VERSION ""

NS_ :

BS_:

BU_: SimBus RxModel

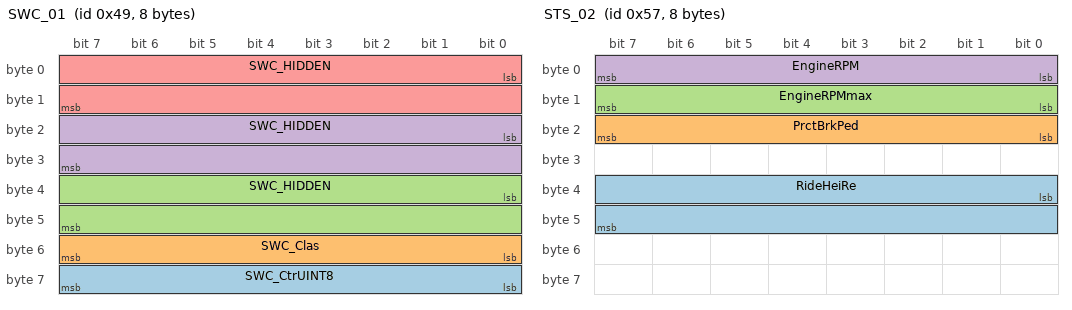
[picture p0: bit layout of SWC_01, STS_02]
BO_ 73 SWC_01: 8 RxModel
 SG_ SWC_CtrUINT8 : 56|8@1+ (1,0) [0|255] "rad" Vector__XXX
 SG_ SWC_Clas : 48|8@1+ (1,0) [0|255] "na" Vector__XXX
 SG_ SWC_HIDDEN : 32|16@1+ (1.06526489E-007,-0.00349066) [-0.00349066|0.003490553456615] "rad" Vector__XXX
 SG_ SWC_HIDDEN : 16|16@1+ (5.999E-006,-0.19659) [-0.19659|0.196554465] "rad" Vector__XXX
 SG_ SWC_HIDDEN : 0|16@1+ (5.999E-006,-0.19659) [-0.19659|0.196554465] "rad" Vector__XXX

BO_ 87 STS_02: 8 SimBus
 SG_ RideHeiRe : 32|16@1+ (0.005,-163.84) [-163.84|163.835] "mps2"  RxModel
 SG_ PrctBrkPed : 16|8@1+ (1,0) [0|255] ""  RxModel
 SG_ EngineRPMmax : 8|8@1+ (50,0) [0|12750] ""  RxModel
 SG_ EngineRPM : 0|8@1+ (50,0) [0|12750] ""  RxModel

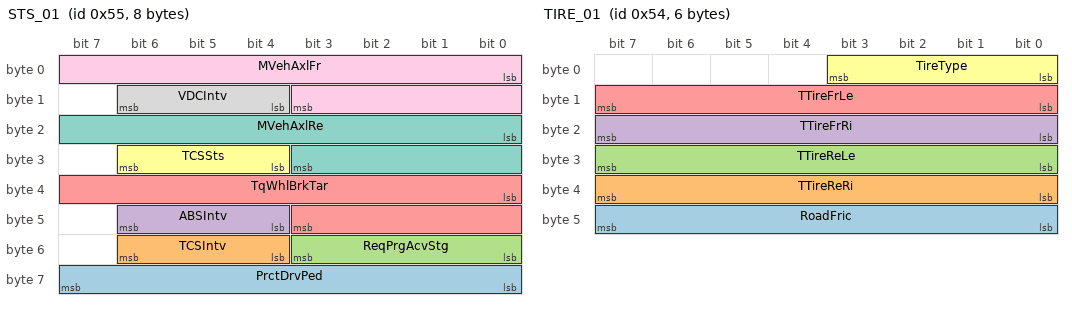
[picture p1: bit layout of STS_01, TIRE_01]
BO_ 85 STS_01: 8 SimBus
 SG_ PrctDrvPed : 56|8@1+ (1,0) [0|255] ""  RxModel
 SG_ TCSIntv : 52|3@1+ (1,0) [0|7] ""  RxModel
 SG_ ReqPrgAcvStg : 48|4@1+ (1,0) [0|15] ""  RxModel
 SG_ ABSIntv : 44|3@1+ (1,0) [0|7] ""  RxModel
 SG_ TqWhlBrkTar : 32|12@1+ (5,0) [0|20475] ""  RxModel
 SG_ TCSSts : 28|3@1+ (1,0) [0|7] ""  RxModel
 SG_ MVehAxlRe : 16|12@1+ (1,0) [0|4095] ""  RxModel
 SG_ VDCIntv : 12|3@1+ (1,0) [0|7] ""  RxModel
 SG_ MVehAxlFr : 0|12@1+ (1,0) [0|4095] ""  RxModel

BO_ 84 TIRE_01: 6 SimBus
 SG_ RoadFric : 40|8@1+ (0.01,0) [0|2.55] ""  RxModel
 SG_ TTireReRi : 32|8@1+ (1,-25) [-25|230] "deg"  RxModel
 SG_ TTireReLe : 24|8@1+ (1,-25) [-25|230] "deg"  RxModel
 SG_ TTireFrRi : 16|8@1+ (1,-25) [-25|230] "deg"  RxModel
 SG_ TTireFrLe : 8|8@1+ (1,-25) [-25|230] "deg"  RxModel
 SG_ TireType : 0|4@1+ (1,0) [0|15] ""  RxModel

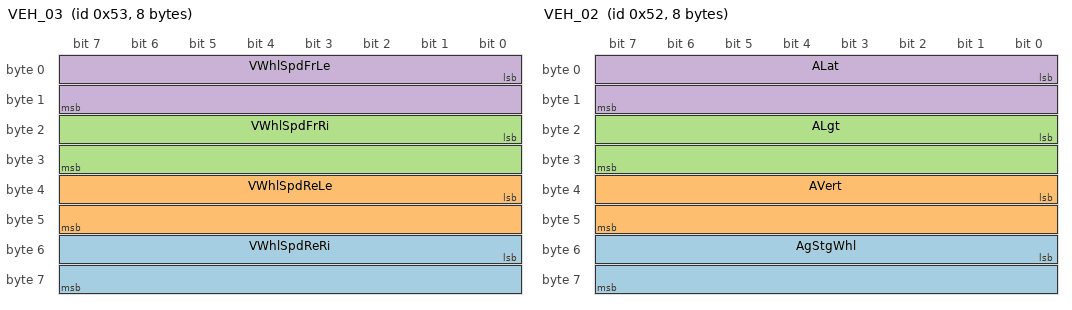
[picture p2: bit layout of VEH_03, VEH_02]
BO_ 83 VEH_03: 8 SimBus
 SG_ VWhlSpdReRi : 48|16@1+ (0.0039,-127.7874) [-127.7874|127.7991] "mps"  RxModel
 SG_ VWhlSpdReLe : 32|16@1+ (0.0039,-127.7874) [-127.7874|127.7991] "mps"  RxModel
 SG_ VWhlSpdFrRi : 16|16@1+ (0.0039,-127.7874) [-127.7874|127.7991] "mps"  RxModel
 SG_ VWhlSpdFrLe : 0|16@1+ (0.0039,-127.7874) [-127.7874|127.7991] "mps"  RxModel

BO_ 82 VEH_02: 8 SimBus
 SG_ AgStgWhl : 48|16@1+ (0.000436252413289189,-14.2942465738336) [-14.2942465738336|14.2955553310734] "rad"  RxModel
 SG_ AVert : 32|16@1+ (0.005,-163.84) [-163.84|163.835] "mps2"  RxModel
 SG_ ALgt : 16|16@1+ (0.005,-163.84) [-163.84|163.835] "mps2"  RxModel
 SG_ ALat : 0|16@1+ (0.005,-163.84) [-163.84|163.835] "mps2"  RxModel

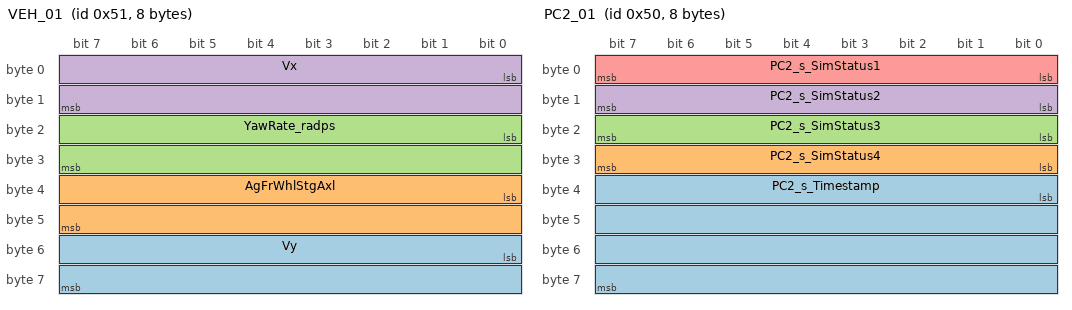
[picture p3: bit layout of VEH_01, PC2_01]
BO_ 81 VEH_01: 8 SimBus
 SG_ Vy : 48|16@1+ (0.0039,-127.7874) [-127.7874|127.7991] "mps" Vector__XXX
 SG_ AgFrWhlStgAxl : 32|16@1+ (3.19598837574497E-005,-1.0471975511966) [-1.0471975511966|1.04729343084787] "rad"  RxModel
 SG_ YawRate_radps : 16|16@1+ (0.000174532925199433,-5.71909489293502) [-5.71909489293502|5.71892036000982] "radps"  RxModel
 SG_ Vx : 0|16@1+ (0.0039,-127.7874) [-127.7874|127.7991] "mps"  RxModel

BO_ 80 PC2_01: 8 SimBus
 SG_ PC2_s_Timestamp : 32|32@1+ (1,0) [0|1.84467440737096E+019] ""  RxModel
 SG_ PC2_s_SimStatus4 : 24|8@1+ (1,0) [0|255] "na"  RxModel
 SG_ PC2_s_SimStatus3 : 16|8@1+ (1,0) [0|255] "na"  RxModel
 SG_ PC2_s_SimStatus2 : 8|8@1+ (1,0) [0|255] "na"  RxModel
 SG_ PC2_s_SimStatus1 : 0|8@1+ (1,0) [0|255] "na"  RxModel

CM_ SG_ 84 TireType "0Winter
1Summer
2AllSeason
3Offroad
4UltraHighPerformance
5EDistance
6EPerformance
7SpareTire
8SummerSport
";
BA_DEF_  "BusType" STRING ;
BA_DEF_DEF_  "BusType" "CAN";
